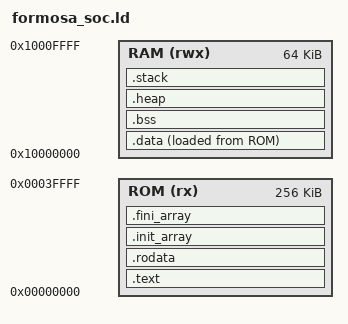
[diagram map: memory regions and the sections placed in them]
/**
 * @file formosa_soc.ld
 * @brief FormosaSoC RISC-V 連結器腳本
 *
 * 設計理念：
 *   本連結器腳本定義 FormosaSoC 的記憶體佈局和程式區段配置。
 *
 *   記憶體配置：
 *     - ROM (Flash): 0x00000000, 256KB
 *       存放程式碼（.text）、唯讀資料（.rodata）和 DATA 初始值
 *
 *     - RAM (SRAM):  0x10000000, 64KB
 *       存放可讀寫資料（.data）和未初始化資料（.bss）
 *       堆疊位於 RAM 頂端，向低位址成長
 *
 *   區段配置順序（ROM 中）：
 *     .text → .rodata → .data（初始值）
 *
 *   區段配置順序（RAM 中）：
 *     .data → .bss → （可用空間）→ heap → stack
 *
 *   堆疊大小：預設 4KB，可透過 __stack_size 符號調整。
 */

/* =========================================================================
 *  記憶體區域定義
 *  說明：定義晶片可用的記憶體區域和存取權限。
 *    r = 可讀取
 *    w = 可寫入
 *    x = 可執行
 * ========================================================================= */
MEMORY
{
    ROM (rx)  : ORIGIN = 0x00000000, LENGTH = 256K   /* 程式碼儲存空間 */
    RAM (rwx) : ORIGIN = 0x10000000, LENGTH = 64K    /* 資料記憶體空間 */
}

/* =========================================================================
 *  堆疊大小定義
 *  說明：可在命令列以 -Wl,--defsym=__stack_size=0x2000 覆寫。
 * ========================================================================= */
__stack_size = DEFINED(__stack_size) ? __stack_size : 0x1000; /* 預設 4KB */
__heap_size  = DEFINED(__heap_size)  ? __heap_size  : 0x2000; /* 預設 8KB */

/* =========================================================================
 *  程式入口點
 * ========================================================================= */
ENTRY(_start)

/* =========================================================================
 *  區段定義
 * ========================================================================= */
SECTIONS
{
    /* =====================================================================
     *  .text 區段：程式碼
     *  說明：存放在 ROM 中，包含中斷向量表和所有函式的機器碼。
     *        .text.init 置於最前面，確保重設向量在 0x00000000。
     * ===================================================================== */
    .text : ALIGN(4)
    {
        *(.text.init)           /* 啟動程式碼（必須在最前面） */
        . = ALIGN(256);         /* 向量表需要 256 位元組對齊 */
        *(.text.vectors)        /* 中斷向量表 */
        *(.text .text.*)        /* 所有其他程式碼 */
    } > ROM

    /* =====================================================================
     *  .rodata 區段：唯讀資料
     *  說明：存放在 ROM 中，包含字串常數、const 變數等。
     * ===================================================================== */
    .rodata : ALIGN(4)
    {
        *(.rodata .rodata.*)    /* 唯讀資料 */
        *(.srodata .srodata.*)  /* 小型唯讀資料（RISC-V 專用） */
    } > ROM

    /* =====================================================================
     *  .init_array 區段：全域建構子
     *  說明：存放 C++ 全域物件建構子或 __attribute__((constructor))
     *        修飾函式的指標陣列。啟動時由 crt0.c 遍歷呼叫。
     * ===================================================================== */
    .init_array : ALIGN(4)
    {
        __init_array_start = .;
        KEEP(*(.init_array))
        KEEP(*(SORT(.init_array.*)))
        __init_array_end = .;
    } > ROM

    /* =====================================================================
     *  .fini_array 區段：全域解構子
     * ===================================================================== */
    .fini_array : ALIGN(4)
    {
        __fini_array_start = .;
        KEEP(*(.fini_array))
        KEEP(*(SORT(.fini_array.*)))
        __fini_array_end = .;
    } > ROM

    /* =====================================================================
     *  .data 區段：已初始化的可讀寫資料
     *  說明：
     *    此區段的內容在執行時位於 RAM 中（AT> ROM 表示初始值存在 ROM）。
     *    啟動程式碼（startup.S）負責將初始值從 ROM 複製到 RAM。
     *
     *    連結器提供三個符號：
     *      __data_start：RAM 中的起始位址
     *      __data_end：  RAM 中的結束位址
     *      __data_load：  ROM 中的初始值位址
     * ===================================================================== */
    .data : ALIGN(4)
    {
        __data_start = .;
        *(.data .data.*)        /* 已初始化全域變數 */
        *(.sdata .sdata.*)      /* 小型已初始化資料（RISC-V 專用） */

        /* 全域指標位址（RISC-V 使用 gp 暫存器加速全域變數存取）
         * 將 __global_pointer$ 設在 .sdata 區段中間，
         * 使 ±2KB 範圍內的變數可用單一指令存取 */
        . = ALIGN(8);
        PROVIDE(__global_pointer$ = . + 0x800);

        __data_end = .;
    } > RAM AT> ROM

    /* DATA 區段在 ROM 中的載入位址（供啟動程式碼使用） */
    __data_load = LOADADDR(.data);

    /* =====================================================================
     *  .bss 區段：未初始化的可讀寫資料
     *  說明：
     *    此區段在 RAM 中，啟動程式碼會將其全部清零。
     *    不佔用 ROM 空間（只記錄大小）。
     * ===================================================================== */
    .bss (NOLOAD) : ALIGN(4)
    {
        __bss_start = .;
        *(.bss .bss.*)          /* 未初始化全域變數 */
        *(.sbss .sbss.*)        /* 小型未初始化資料 */
        *(COMMON)               /* C 語言的 tentative definitions */
        __bss_end = .;
    } > RAM

    /* =====================================================================
     *  堆積（Heap）區域
     *  說明：
     *    動態記憶體配置區域（malloc 等函式使用）。
     *    位於 BSS 之後，堆疊之前。
     * ===================================================================== */
    .heap (NOLOAD) : ALIGN(8)
    {
        __heap_start = .;
        . = . + __heap_size;
        __heap_end = .;
    } > RAM

    /* =====================================================================
     *  堆疊（Stack）區域
     *  說明：
     *    位於 RAM 頂端，向低位址成長（高位址 → 低位址）。
     *    __stack_top 為堆疊初始值（RAM 最頂端）。
     * ===================================================================== */
    .stack (NOLOAD) : ALIGN(16)
    {
        __stack_bottom = .;
        . = . + __stack_size;
        __stack_top = .;
    } > RAM

    /* =====================================================================
     *  記憶體使用量檢查
     *  說明：確保各區段沒有超出可用記憶體空間。
     * ===================================================================== */
    ASSERT(__stack_top <= ORIGIN(RAM) + LENGTH(RAM),
           "Error: Stack exceeds available RAM!")

    ASSERT((__data_end - __data_start) + (__bss_end - __bss_start)
           + __heap_size + __stack_size <= LENGTH(RAM),
           "Error: RAM sections exceed available RAM!")

    /* =====================================================================
     *  除錯資訊（不佔用目標記憶體空間）
     * ===================================================================== */
    /DISCARD/ :
    {
        *(.comment)
        *(.note.*)
    }
}

/* =========================================================================
 *  有用的符號輸出
 *  說明：提供記憶體佈局資訊，可在韌體中使用。
 * ========================================================================= */
__rom_start  = ORIGIN(ROM);
__rom_size   = LENGTH(ROM);
__ram_start  = ORIGIN(RAM);
__ram_size   = LENGTH(RAM);
